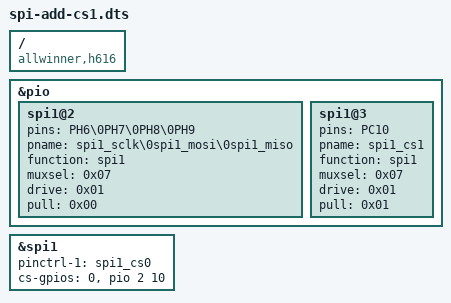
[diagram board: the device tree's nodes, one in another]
/dts-v1/;
/plugin/;

/ {
	compatible = "allwinner,h616", "arm,sun50iw9p1", "allwinner,sun50i-h6", "arm,sun50iw6p1";

	fragment@0 {
		target = <&pio>;
		__overlay__ {
			spi1@2 {
				pins = "PH6\0PH7\0PH8\0PH9";
				pname = "spi1_sclk\0spi1_mosi\0spi1_miso";
				function = "spi1";
				muxsel = < 0x07 >;
				drive = < 0x01 >;
				pull = < 0x00 >;
				phandle = < 0x84 >;
			};
			spi1@3 {
				pins = "PC10";
				pname = "spi1_cs1";
				function = "spi1";
				muxsel = < 0x07 >;
				drive = < 0x01 >;
				pull = < 0x01 >;
				phandle = < 0x85 >;
			};
		};
	};

	fragment@1 {
		target = <&spi1>;
		__overlay__ {
			pinctrl-names = "default", "default";
			pinctrl-1 = <&spi1_cs0>;
			cs-gpios = <0>, <&pio 2 10 0>; /* PL8 */
		};
	};
};
